# GD32A72_A74x register map
File version: 1.0
CPU: CM7 r2p1, little endian, MPU, FPU, DSP, 4 interrupt priority bits
Registers are 32-bit, read-write, reset 0x0 unless marked. A register's access mark holds for its fields unless they carry their own. Offsets are from the block's base; [hi:lo] are bit positions; {n}, {i} and the like mark numbered series.

## TIMER1 — General level0 timer
Base 0x40015C00
Same registers: TIMER2 0x40000400
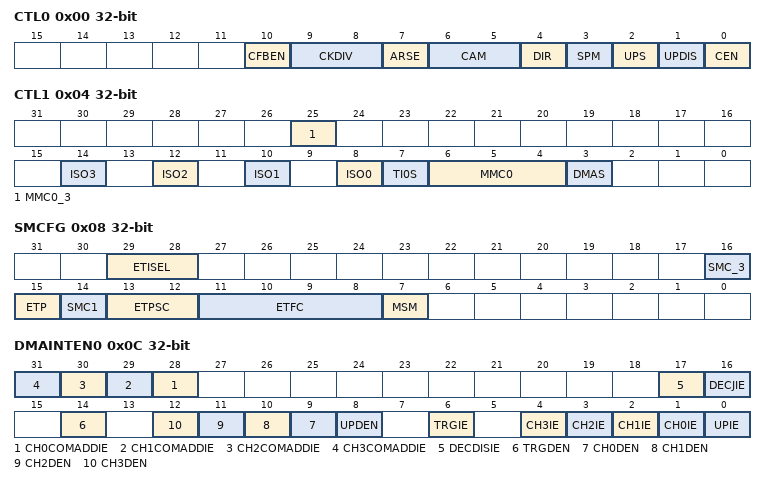
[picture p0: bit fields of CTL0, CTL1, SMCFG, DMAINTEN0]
0x00 CTL0 — Control register 0
  [10] CFBEN — Couter freeze in break mode enable
  [9:8] CKDIV — Clock division
  [7] ARSE — Auto-reload shadow enable
  [6:5] CAM — Counter align mode selection
  [4] DIR — Direction
  [3] SPM — Single pulse mode
  [2] UPS — Update source
  [1] UPDIS — Update disable
  [0] CEN — Counter enable
0x04 CTL1 — Control register 1
  [25] MMC0_3 — Refer to MMC0[2:0] description
  [14] ISO3 — Must be kept at reset value
  [12] ISO2 — Must be kept at reset value
  [10] ISO1 — Idle state of multi mode channel 1 complementary output
  [8] ISO0 — Must be kept at reset value
  [7] TI0S — Idle state of channel 0 output
  [6:4] MMC0 — Channel 0 trigger input selection
  [3] DMAS — Master mode control
0x08 SMCFG — Slave mode configuration register
  [29:28] ETISEL — TIMER0 external trigger select
  [16] SMC_3 — Refer to SMC[2:0]
  [15] ETP — External trigger polarity
  [14] SMC1 — Part of SMC is used to enable external clock mode 1
  [13:12] ETPSC — The prescaler of external trigger
  [11:8] ETFC — External trigger filter control
  [7] MSM — Master-slave mode
0x0C DMAINTEN0 — DMA and interrupt enable register 0
  [n+28] CH{n}COMADDIE (n=0..3) — Channel {n} additional compare interrupt enable
  [17] DECDISIE — Quadrature decoder signal disconnection interrupt enable
  [16] DECJIE — Quadrature decoder signal jump (the two signals jump at the same time) interrupt enable
  [14] TRGDEN — Trigger DMA request enable
  [n+9] CH{n}DEN (n=0..3) — Channel {n} capture/compare DMA request enable
  [8] UPDEN — Update DMA request enable
  [6] TRGIE — Trigger interrupt enable
  [n+1] CH{n}IE (n=0..3) — Channel {n} capture/compare interrupt enable
  [0] UPIE — Update interrupt enable
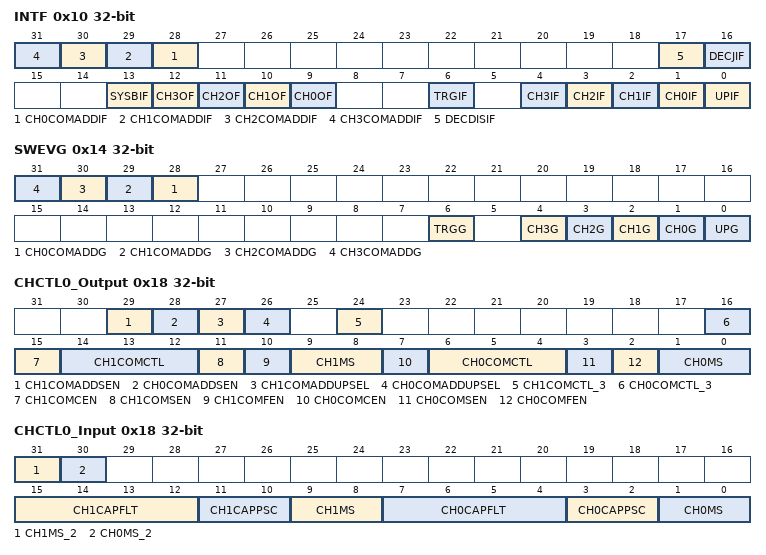
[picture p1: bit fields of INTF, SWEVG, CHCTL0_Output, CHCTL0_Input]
0x10 INTF — Interrupt flag register
  [n+28] CH{n}COMADDIF (n=0..3) — Channel {n} additional compare interrupt flag
  [17] DECDISIF — Quadrature decoder signal disconnection interrupt flag
  [16] DECJIF — Quadrature decoder signal jump (the two signals jump at the same time) interrupt flag
  [13] SYSBIF — System source break interrupt flag
  [n+9] CH{n}OF (n=0..3) — Channel {n} over capture flag
  [6] TRGIF — Trigger interrupt flag
  [n+1] CH{n}IF (n=0..3) — Channel {n} capture/compare interrupt flag
  [0] UPIF — Update interrupt flag
0x14 SWEVG wo — Software event generation register
  [n+28] CH{n}COMADDG (n=0..3) — Channel {n} additional compare event generation
  [6] TRGG — Trigger event generation
  [n+1] CH{n}G (n=0..3) — Channel {n} capture or compare event generation
  [0] UPG — Update event generation
0x18 CHCTL0_Output — Channel control register 0 (output mode)
  [29] CH1COMADDSEN — Channel 1 additional compare output shadow enable
  [28] CH0COMADDSEN — Channel 0 additional compare output shadow enable
  [27] CH1COMADDUPSEL — Refer to CH0COMADDUPSEL
  [26] CH0COMADDUPSEL — Update selection of channel 0 additional compare value
  [24] CH1COMCTL_3 — Refer to CH1COMCTL[2:0]
  [16] CH0COMCTL_3 — Refer to CH0COMCTL[2:0]
  [15] CH1COMCEN — Channel 1 output compare clear enable
  [14:12] CH1COMCTL — Channel 1 compare output control
  [11] CH1COMSEN — Channel 1 output compare shadow enable
  [10] CH1COMFEN — Channel 1 output compare fast enable
  [9:8] CH1MS — Channel 1 mode selection
  [7] CH0COMCEN — Channel 0 output compare clear enable
  [6:4] CH0COMCTL — Channel 0 compare output control
  [3] CH0COMSEN — Channel 0 compare output shadow enable
  [2] CH0COMFEN — Channel 0 output compare fast enable
  [1:0] CH0MS — Channel 0 I/O mode selection
0x18 CHCTL0_Input (alternate view of CHCTL0_Output) — Channel control register 0 (input mode)
  [31] CH1MS_2 — Channel 1 I/O mode selection
  [30] CH0MS_2 — Channel 0 I/O mode selection
  [15:12] CH1CAPFLT — Channel 1 input capture filter control
  [11:10] CH1CAPPSC — Channel 1 input capture prescaler
  [9:8] CH1MS — Channel 1 mode selection
  [7:4] CH0CAPFLT — Channel 0 input capture filter control
  [3:2] CH0CAPPSC — Channel 0 input capture prescaler
  [1:0] CH0MS — Channel 0 I/O mode selection
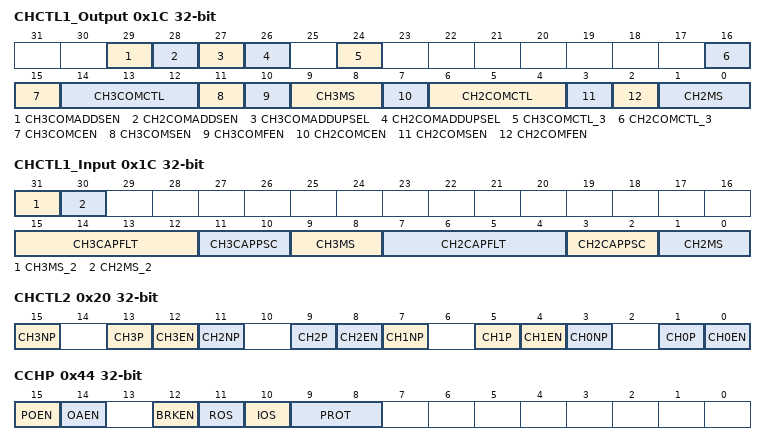
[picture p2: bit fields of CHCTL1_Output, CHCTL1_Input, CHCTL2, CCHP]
0x1C CHCTL1_Output — Channel control register 1 (output mode)
  [29] CH3COMADDSEN — Channel 3 additional compare output shadow enable
  [28] CH2COMADDSEN — Channel 2 additional compare output shadow enable
  [27] CH3COMADDUPSEL — Refer to CH0COMADDUPSEL
  [26] CH2COMADDUPSEL — Update selection of channel 2 additional compare value
  [24] CH3COMCTL_3 — Refer to CH3COMCTL[2:0]
  [16] CH2COMCTL_3 — Refer to CH2COMCTL[2:0]
  [15] CH3COMCEN — Channel 3 output compare clear enable
  [14:12] CH3COMCTL — Channel 3 compare output control
  [11] CH3COMSEN — Channel 3 output compare shadow enable
  [10] CH3COMFEN — Channel 3 output compare fast enable
  [9:8] CH3MS — Channel 3 I/O mode selection
  [7] CH2COMCEN — Channel 2 output compare clear enable
  [6:4] CH2COMCTL — Channel 1 output compare shadow enable
  [3] CH2COMSEN — Channel 2 output compare shadow enable
  [2] CH2COMFEN — Channel 2 output compare fast enable
  [1:0] CH2MS — Channel 2 I/O mode selection
0x1C CHCTL1_Input (alternate view of CHCTL1_Output) — Channel control register 1 (input mode)
  [31] CH3MS_2 — Channel 3 I/O mode selection
  [30] CH2MS_2 — Channel 2 I/O mode selection
  [15:12] CH3CAPFLT — Channel 3 input capture filter control
  [11:10] CH3CAPPSC — Channel 3 input capture prescaler
  [9:8] CH3MS — Channel 3 mode selection
  [7:4] CH2CAPFLT — Channel 2 input capture filter control
  [3:2] CH2CAPPSC — Channel 2 input capture prescaler
  [1:0] CH2MS — Channel 2 I/O mode selection
0x20 CHCTL2 — Channel control register 2
  [15] CH3NP — Channel 3 complementary capture/compare polarity
  [4n+1] CH{n}P (n=0..3) — Channel {n} capture/compare function polarity
  [4n] CH{n}EN (n=0..3) — Channel {n} capture/compare function enable
  [11] CH2NP — Channel 2 complementary capture/compare polarity
  [7] CH1NP — Channel 1 complementary capture/compare polarity
  [3] CH0NP — Channel 0 complementary output polarity
0x24 CNT — Counter register
  [15:0] CNT — This bit-field indicates the current counter value
0x28 PSC — Prescaler register
  [15:0] PSC — Prescaler value of the counter clock
0x2C CAR — Counter auto reload register
  [15:0] CARL — Counter auto reload value
{0x34+4i} CH{i}CV (i=0..3) — Channel {i} capture/compare value register
  [15:0] CH{i}VAL — Capture/compare value of channel {i}
0x44 CCHP — Complementary channel protection register
  [15] POEN — Primary output enable
  [14] OAEN — Output automatic enable
  [12] BRKEN — BRKINx(x = 0..3) input signals enable
  [11] ROS — Run mode off-state enable
  [10] IOS — Idle mode off-state enable
  [9:8] PROT — Complementary register protect control
0x50 IRMP — Input remap register
  [1:0] CI0_RMP — Channel 0 input remap
{0x64+4i} CH{i}CV_ADD (i=0..3) — Channel {i} additional capture/compare value register
  [15:0] CH{i}VAL_ADD — Additional capture/compare value of channel {i}
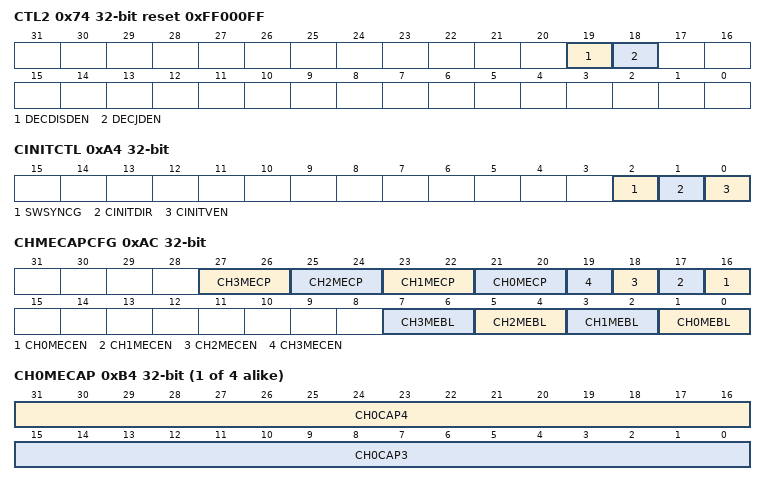
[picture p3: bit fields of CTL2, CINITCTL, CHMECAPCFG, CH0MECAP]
0x74 CTL2 reset 0xFF000FF — Control register 2
  [19] DECDISDEN — Quadrature decoder signal disconnection detection enable
  [18] DECJDEN — Quadrature decoder signal jump (the two signals jump at the same time) detection enable
0xA0 WDGPER reset 0xFFFFFFFF — Watchdog counter period register
  [31:0] WDGPER — Watchdog counter period value
0xA4 CINITCTL — Counter initial control register
  [2] SWSYNCG — Software synchronization event generation
  [1] CINITDIR — Counter initial count direction
  [0] CINITVEN — Counter initial value register enable
0xA8 CINITV — Counter initial value register
  [15:0] CINITVAL — Counter initial value
0xAC CHMECAPCFG — Channel multi-edge capture configuration register
  [27:26] CH3MECP — Channel 3 multi-edge capture polarity
  [25:24] CH2MECP — Channel 2 multi-edge capture polarity
  [23:22] CH1MECP — Channel 1 multi-edge capture polarity
  [21:20] CH0MECP — Channel 0 multi edge capture polarity
  [n+16] CH{n}MECEN (n=0..3) — Channel {n} multi edge capture enable
  [2n+1:2n] CH{n}MEBL (n=0..3) — Channel {n} multi edge buffer level
{0xB4+4i} CH{i}MECAP ro (i=0..3) — Channel {i} multi-edge capture register
  [31:16] CH{i}CAP4 — Channel {i} captures 4 count values
  [15:0] CH{i}CAP3 — Channel {i} captures 3 count values
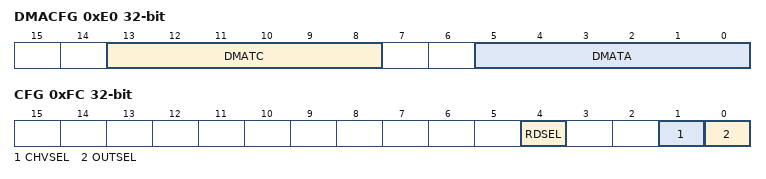
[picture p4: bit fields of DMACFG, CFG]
0xE0 DMACFG — DMA configuration register
  [13:8] DMATC — DMA transfer count
  [5:0] DMATA — DMA transfer access start address
0xE4 DMATB — DMA transfer buffer register
  [15:0] DMATB — DMA transfer buffer
0xFC CFG — Configuration register
  [4] RDSEL — This bit determines the value of TIMER1_PSC, TIMER1_CAR, TIMER1_CHyCV, TIMER1_MCHyCV, TIMER1_CHyCV_ADD when reading the register
  [1] CHVSEL — Write CHxVAL register selection bit
  [0] OUTSEL — The output value selection bit
